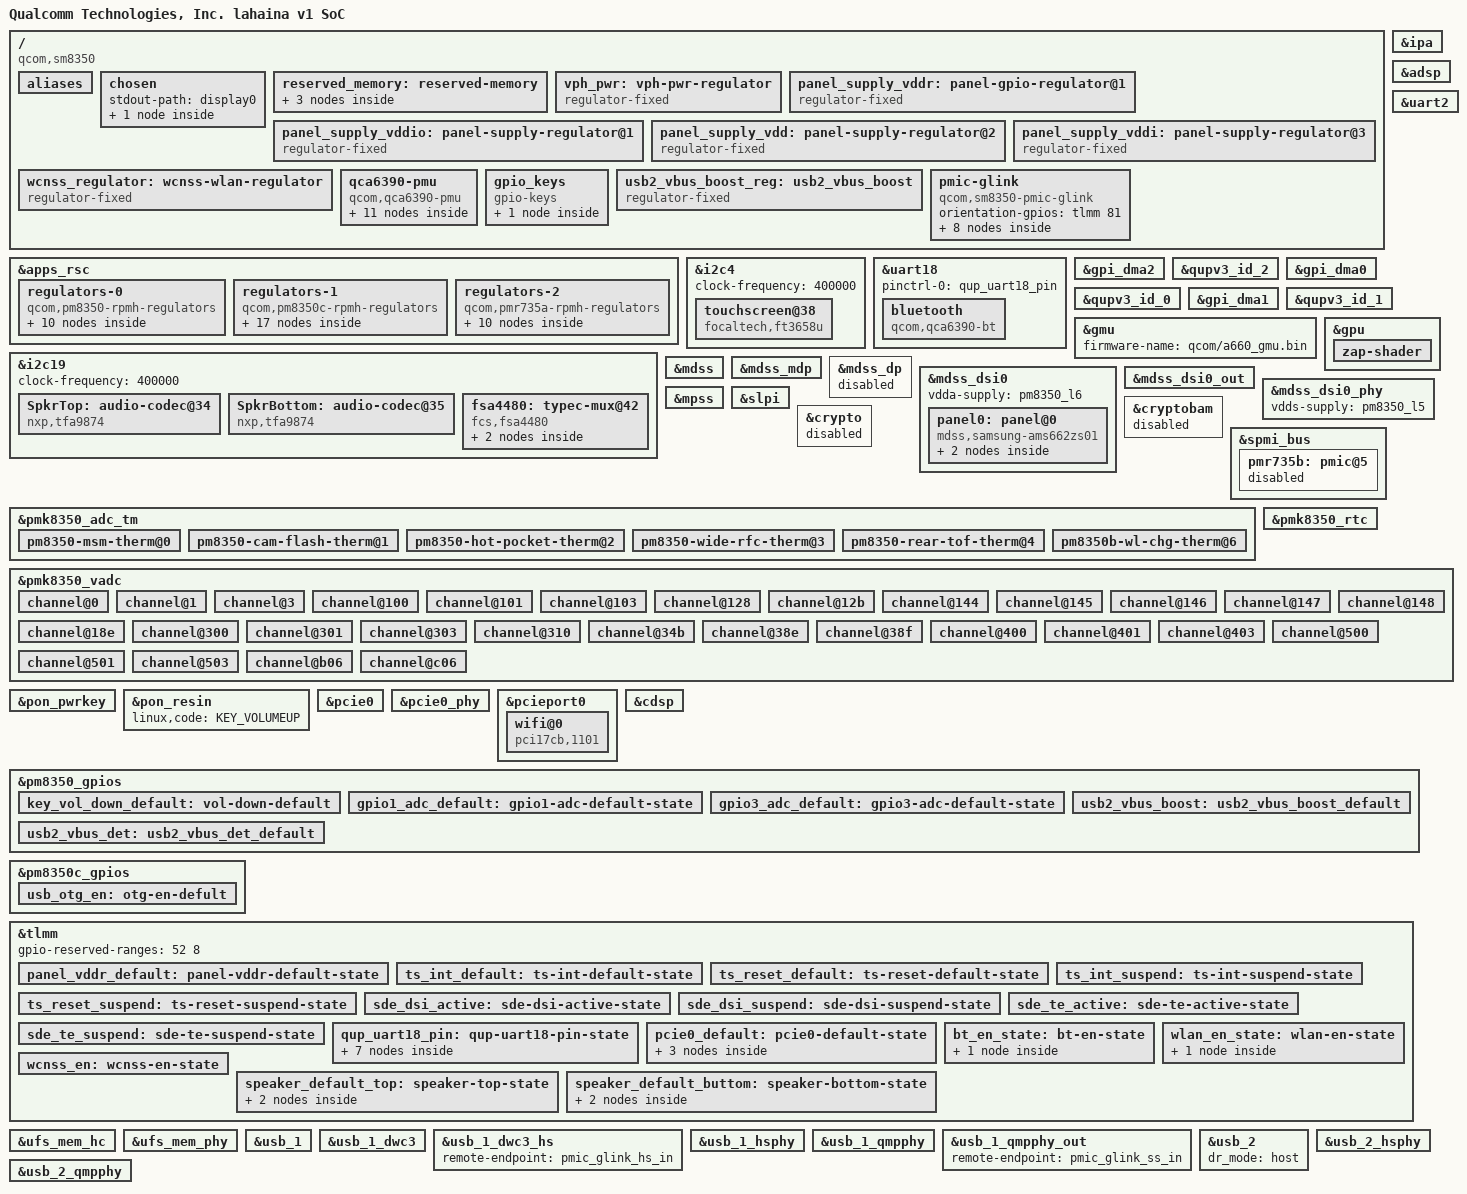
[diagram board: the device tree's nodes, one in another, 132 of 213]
/dts-v1/;

#include <dt-bindings/gpio/gpio.h>
#include <dt-bindings/usb/pd.h>
#include <dt-bindings/arm/qcom,ids.h>
#include <dt-bindings/phy/phy.h>
#include <dt-bindings/interrupt-controller/arm-gic.h>
#include <dt-bindings/regulator/qcom,rpmh-regulator.h>
#include <dt-bindings/dma/qcom-gpi.h>
#include <dt-bindings/pinctrl/qcom,pmic-gpio.h>
#define SMB139x_1_SID 0x0b
#define SMB139x_2_SID 0x0c
#include <dt-bindings/iio/qcom,spmi-adc7-smb139x.h>
#include <dt-bindings/iio/qcom,spmi-adc7-pm8350.h>
#include <dt-bindings/iio/qcom,spmi-adc7-pm8350b.h>
#include <dt-bindings/iio/qcom,spmi-adc7-pmk8350.h>
#include <dt-bindings/iio/qcom,spmi-adc7-pmr735a.h>
#include <dt-bindings/iio/qcom,spmi-adc7-pmr735b.h>
#include "sm8350.dtsi"
#include "pm8350.dtsi"
#include "pm8350b.dtsi"
#include "pm8350c.dtsi"
#include "pmk8350.dtsi"
#include "pmr735a.dtsi"
#include "pmr735b.dtsi"

/ {
	model = "Qualcomm Technologies, Inc. lahaina v1 SoC";
	compatible = "qcom,sm8350", "qcom,lahaina";
	qcom,msm-id = <415 0x10000>, <456 0x10000>;
	qcom,board-id = <0 0>;
        oppo,dtsi_no = <0x5093>;
	interrupt-parent = <&intc>;

	#address-cells = <2>;
	#size-cells = <2>;

        chassis-type = "handset";

	aliases {
                display0 = &panel0;
                serial0 = &uart2;
                hsuart0 = &uart18;
	};

	chosen {
		#address-cells = <2>;
		#size-cells = <2>;
		ranges;
		stdout-path = "display0";

		framebuffer0: framebuffer@e4d00000 {
			compatible = "simple-framebuffer";
			reg = <0x0 0xe4d00000 0x0 0x02300000>;
			width = <1080>;
			height = <2400>;
			stride = <(1080 * 4)>;
			format = "a8r8g8b8";
			clocks = <&gcc GCC_DISP_HF_AXI_CLK>,
				 <&gcc GCC_DISP_SF_AXI_CLK>;
		};
	};

        reserved_memory: reserved-memory {
		#address-cells = <2>;
		#size-cells = <2>;
		ranges;

                splash_memory@e4d00000 {
                        reg = <0x0 0xe4d00000 0x0 0x02300000>;
                        no-map;
                        label = "cont_splash_region";
                };

                ramoops@e9700000 {
                        compatible = "ramoops";
                        reg = <0x0 0xe9700000 0x0 0x05B8000>;
                        record-size = <0x40000>;
                        console-size = <0x40000>;
                        ftrace-size = <0x200000>;
                        pmsg-size = <0x200000>;
                };

                kboot_uboot_logmem@9fe00000 {
                        compatible = "oppo,xbl_uefi_kbootlog";
	                xbluefi-offset = <0x1f7000>;
	                reg = <0x00 0x9fe00000 0x00 0x200000>;
	                phandle = <0x6f5>;
                        no-map;
                };
        };

	vph_pwr: vph-pwr-regulator {
		compatible = "regulator-fixed";
		regulator-name = "vph_pwr";
		regulator-min-microvolt = <3700000>;
		regulator-max-microvolt = <3700000>;
		regulator-always-on;
		regulator-boot-on;
	};

        panel_supply_vddr: panel-gpio-regulator@1 {
                compatible = "regulator-fixed";
                regulator-name = "panel_supply_vddr";
                regulator-min-microvolt = <1800000>;
                regulator-max-microvolt = <1800000>;
                gpio = <&tlmm 163 0x0>;
                enable-active-high;
                regulator-boot-on;
                pinctrl-names = "default";
                pinctrl-0 = <&panel_vddr_default>;

        };

        panel_supply_vddio: panel-supply-regulator@1 {
                compatible = "regulator-fixed";
                regulator-name = "panel_supply_vddio";
                regulator-min-microvolt = <1800000>;
                regulator-max-microvolt = <1800000>;
                regulator-enable-load = <60700>;
                regulator-disable-load = <80>;
                regulator-post-on-sleep = <0>;
        };

        panel_supply_vdd: panel-supply-regulator@2 {
                compatible = "regulator-fixed";
                regulator-name = "panel_supply_vdd";
                regulator-min-microvolt = <3000000>;
                regulator-max-microvolt = <3000000>;
                regulator-enable-load = <10000>;
                regulator-disable-load = <0>;
                regulator-post-on-sleep = <0>;
        };

        panel_supply_vddi: panel-supply-regulator@3 {
                compatible = "regulator-fixed";
                regulator-name = "panel_supply_vddi";
                regulator-min-microvolt = <1800000>;
                regulator-max-microvolt = <1800000>;
        };

        wcnss_regulator: wcnss-wlan-regulator {
                compatible = "regulator-fixed";
                regulator-name = "wcnss_regulator";
                regulator-min-microvolt = <1900000>;
                regulator-max-microvolt = <1900000>;
                enable-active-high;
                wcnss-gpio = <&tlmm 201 GPIO_ACTIVE_HIGH>;
                pinctrl-names = "default";
                pinctrl-0 = <&wcnss_en>;
        };

        qca6390-pmu {
                compatible = "qcom,qca6390-pmu";

                pinctrl-names = "default";
                pinctrl-0 = <&bt_en_state>, <&wlan_en_state>;

                vddaon-supply = <&pmr735a_s2>;
                vddpmu-supply = <&pmr735a_s2>;
                vddrfa0p95-supply = <&pmr735a_s2>;
                vddrfa1p3-supply = <&pm8350_s12>;
                vddrfa1p9-supply = <&pm8350c_s1>;
                vddpcie1p3-supply = <&wcnss_regulator>;
                vddpcie1p9-supply = <&pm8350c_s1>;
                vddio-supply = <&pm8350_s10>;

                bt-enable-gpios = <&tlmm 65 GPIO_ACTIVE_HIGH>;
                wlan-enable-gpios = <&tlmm 64 GPIO_ACTIVE_HIGH>;

                regulators {
                        vreg_pmu_rfa_cmn: ldo0 {
                                regulator-name = "vreg_pmu_rfa_cmn";
                        };

                        vreg_pmu_aon_0p59: ldo1 {
                                regulator-name = "vreg_pmu_aon_0p59";
                        };

                        vreg_pmu_wlcx_0p8: ldo2 {
                                regulator-name = "vreg_pmu_wlcx_0p8";
                        };

                        vreg_pmu_wlmx_0p85: ldo3 {
                                regulator-name = "vreg_pmu_wlmx_0p85";
                        };

                        vreg_pmu_btcmx_0p85: ldo4 {
                                regulator-name = "vreg_pmu_btcmx_0p85";
                        };

                        vreg_pmu_rfa_0p8: ldo5 {
                                regulator-name = "vreg_pmu_rfa_0p8";
                        };

                        vreg_pmu_rfa_1p2: ldo6 {
                                regulator-name = "vreg_pmu_rfa_1p2";
                        };

                        vreg_pmu_rfa_1p7: ldo7 {
                                regulator-name = "vreg_pmu_rfa_1p7";
                        };

                        vreg_pmu_pcie_0p9: ldo8 {
                                regulator-name = "vreg_pmu_pcie_0p9";
                        };

                        vreg_pmu_pcie_1p8: ldo9 {
                                regulator-name = "vreg_pmu_pcie_1p8";
                        };
                };
        };

        gpio_keys {
		compatible = "gpio-keys";
		label = "gpio-keys";
		pinctrl-names = "default";
		pinctrl-0 = <&key_vol_down_default>;
		vol_down {
			label = "volume_down";
			gpios = <&pm8350_gpios 6 GPIO_ACTIVE_LOW>;
			linux,input-type = <1>;
			linux,code = <KEY_VOLUMEDOWN>;
			gpio-key,wakeup;
			debounce-interval = <15>;
			linux,can-disable;
		};
	};

        usb2_vbus_boost_reg: usb2_vbus_boost {
                compatible = "regulator-fixed";
                regulator-name = "usb2_vbus_boost";
                regulator-min-microvolt = <5000000>;
                regulator-max-microvolt = <5000000>;
                gpio = <&pm8350_gpios 8 GPIO_ACTIVE_HIGH>;
                enable-active-high;
        };

	pmic-glink {
		compatible = "qcom,sm8350-pmic-glink", "qcom,pmic-glink";
		#address-cells = <1>;
		#size-cells = <0>;

                /*pinctrl-names = "default", "gpio";
                pinctrl-0 = <&usb_phy_ps &usb_phy_ps1>;*/

                orientation-gpios = <&tlmm 81 GPIO_ACTIVE_HIGH>;

		connector@0 {
			compatible = "usb-c-connector";
			reg = <0>;
			power-role = "dual";
			data-role = "dual";
                        usb-role-switch;   // ADD THIS
			ports {
				#address-cells = <1>;
				#size-cells = <0>;
				port@0 {
					reg = <0>;
					pmic_glink_hs_in: endpoint {
						remote-endpoint = <&usb_1_dwc3_hs>;
					};
				};

                                port@1 {
                                        reg = <1>;
                                        pmic_glink_ss_in: endpoint {
                                                remote-endpoint = <&usb_1_qmpphy_out>;
                                        };
                                };

				port@2 {
					reg = <2>;
					pmic_glink_sbu: endpoint {
						remote-endpoint = <&fsa4480_sbu_mux>;
					};
				};
			};
		};
	};
};

&ipa {
	status = "okay";
	qcom,gsi-loader = "self";
	memory-region = <&pil_ipa_fw_mem>;
	firmware-name = "qcom/sm8350/realme/porsche/ipa_fws.mbn";
};

&adsp {
	status = "okay";
        memory-region = <&pil_adsp_mem>;
	firmware-name = "qcom/sm8350/realme/porsche/adsp.mbn";
};

&apps_rsc {
	regulators-0 {
		compatible = "qcom,pm8350-rpmh-regulators";
		qcom,pmic-id = "b";

		vdd-s1-supply = <&vph_pwr>;
		vdd-s2-supply = <&vph_pwr>;
		vdd-s3-supply = <&vph_pwr>;
		vdd-s4-supply = <&vph_pwr>;
		vdd-s5-supply = <&vph_pwr>;
		vdd-s6-supply = <&vph_pwr>;
		vdd-s7-supply = <&vph_pwr>;
		vdd-s8-supply = <&vph_pwr>;
		vdd-s9-supply = <&vph_pwr>;
		vdd-s10-supply = <&vph_pwr>;
		vdd-s11-supply = <&vph_pwr>;
		vdd-s12-supply = <&vph_pwr>;

		vdd-l1-l4-supply = <&pm8350_s11>;
		vdd-l2-l7-supply = <&vreg_bob>;
		vdd-l3-l5-supply = <&vreg_bob>;
		vdd-l6-l9-l10-supply = <&pm8350_s11>;

		pm8350_s10: smps10 {
			regulator-name = "pm8350_s10";
			regulator-min-microvolt = <1800000>;
			regulator-max-microvolt = <1800000>;
		};

		pm8350_s11: smps11 {
			regulator-name = "pm8350_s11";
			regulator-min-microvolt = <752000>;
			regulator-max-microvolt = <1012000>;
		};

		pm8350_s12: smps12 {
			regulator-name = "pm8350_s12";
			regulator-min-microvolt = <1224000>;
			regulator-max-microvolt = <1360000>;
		};

		pm8350_l1: ldo1 {
			regulator-name = "pm8350_l1";
			regulator-min-microvolt = <912000>;
			regulator-max-microvolt = <920000>;
			regulator-initial-mode = <RPMH_REGULATOR_MODE_HPM>;
			regulator-allow-set-load;
			regulator-allowed-modes = <RPMH_REGULATOR_MODE_LPM
						   RPMH_REGULATOR_MODE_HPM>;
		};

		pm8350_l2: ldo2 {
			regulator-name = "pm8350_l2";
			regulator-min-microvolt = <3072000>;
			regulator-max-microvolt = <3072000>;
			regulator-initial-mode = <RPMH_REGULATOR_MODE_HPM>;
			regulator-allow-set-load;
			regulator-allowed-modes = <RPMH_REGULATOR_MODE_LPM
						   RPMH_REGULATOR_MODE_HPM>;
		};

		pm8350_l3: ldo3 {
			regulator-name = "pm8350_l3";
			regulator-min-microvolt = <904000>;
			regulator-max-microvolt = <904000>;
			regulator-initial-mode = <RPMH_REGULATOR_MODE_HPM>;
			regulator-allow-set-load;
			regulator-allowed-modes = <RPMH_REGULATOR_MODE_LPM
						   RPMH_REGULATOR_MODE_HPM>;
		};

		pm8350_l5: ldo5 {
			regulator-name = "pm8350_l5";
			regulator-min-microvolt = <880000>;
			regulator-max-microvolt = <888000>;
			regulator-initial-mode = <RPMH_REGULATOR_MODE_HPM>;
			regulator-allow-set-load;
			regulator-allowed-modes = <RPMH_REGULATOR_MODE_LPM
						   RPMH_REGULATOR_MODE_HPM>;
		};

		pm8350_l6: ldo6 {
			regulator-name = "pm8350_l6";
			regulator-min-microvolt = <1200000>;
			regulator-max-microvolt = <1208000>;
			regulator-initial-mode = <RPMH_REGULATOR_MODE_HPM>;
			regulator-allow-set-load;
			regulator-allowed-modes = <RPMH_REGULATOR_MODE_LPM
						   RPMH_REGULATOR_MODE_HPM>;
		};

		pm8350_l7: ldo7 {
			regulator-name = "pm8350_l7";
			regulator-min-microvolt = <2400000>;
			regulator-max-microvolt = <3008000>;
			regulator-initial-mode = <RPMH_REGULATOR_MODE_HPM>;
			regulator-allow-set-load;
			regulator-allowed-modes = <RPMH_REGULATOR_MODE_LPM
						   RPMH_REGULATOR_MODE_HPM>;
		};

		pm8350_l9: ldo9 {
			regulator-name = "pm8350_l9";
			regulator-min-microvolt = <1200000>;
			regulator-max-microvolt = <1200000>;
			regulator-initial-mode = <RPMH_REGULATOR_MODE_HPM>;
			regulator-allow-set-load;
			regulator-allowed-modes = <RPMH_REGULATOR_MODE_LPM
						   RPMH_REGULATOR_MODE_HPM>;
		};
	};

	regulators-1 {
		compatible = "qcom,pm8350c-rpmh-regulators";
		qcom,pmic-id = "c";
                qcom,always-wait-for-ack = "true";

		vdd-s1-supply = <&vph_pwr>;
		vdd-s2-supply = <&vph_pwr>;
		vdd-s3-supply = <&vph_pwr>;
		vdd-s4-supply = <&vph_pwr>;
		vdd-s5-supply = <&vph_pwr>;
		vdd-s6-supply = <&vph_pwr>;
		vdd-s7-supply = <&vph_pwr>;
		vdd-s8-supply = <&vph_pwr>;
		vdd-s9-supply = <&vph_pwr>;
		vdd-s10-supply = <&vph_pwr>;

		vdd-l1-l12-supply = <&pm8350c_s1>;
		vdd-l2-l8-supply = <&pm8350c_s1>;
		vdd-l3-l4-l5-l7-l13-supply = <&vreg_bob>;
		vdd-l6-l9-l11-supply = <&vreg_bob>;
		vdd-l10-supply = <&pm8350_s12>;

		vdd-bob-supply = <&vph_pwr>;

		pm8350c_s1: smps1 {
			regulator-name = "pm8350c_s1";
			regulator-min-microvolt = <1800000>;
			regulator-max-microvolt = <1952000>;
		};

		pm8350c_s3: smps3 {
			regulator-name = "pm8350c_s3";
			regulator-min-microvolt = <300000>;
			regulator-max-microvolt = <704000>;
		};

		pm8350c_s10: smps10 {
			regulator-name = "pm8350c_s10";
			regulator-min-microvolt = <1048000>;
			regulator-max-microvolt = <1128000>;
		};

                vreg_bob: bob {
		        regulator-name = "vreg_bob";
		        regulator-min-microvolt = <3008000>;
		        regulator-max-microvolt = <3960000>;
		        regulator-initial-mode = <RPMH_REGULATOR_MODE_AUTO>;
	        };

		pm8350c_l1: ldo1 {
			regulator-name = "pm8350c_l1";
			regulator-min-microvolt = <1800000>;
			regulator-max-microvolt = <1800000>;
			regulator-initial-mode = <RPMH_REGULATOR_MODE_HPM>;
			regulator-allow-set-load;
			regulator-allowed-modes = <RPMH_REGULATOR_MODE_LPM
						   RPMH_REGULATOR_MODE_HPM>;
		};

		pm8350c_l2: ldo2 {
			regulator-name = "pm8350c_l2";
			regulator-min-microvolt = <1800000>;
			regulator-max-microvolt = <1800000>;
			regulator-initial-mode = <RPMH_REGULATOR_MODE_HPM>;
			regulator-allow-set-load;
			regulator-allowed-modes = <RPMH_REGULATOR_MODE_LPM
						   RPMH_REGULATOR_MODE_HPM>;
		};

		pm8350c_l3: ldo3 {
			regulator-name = "pm8350c_l3";
			regulator-min-microvolt = <3000000>;
			regulator-max-microvolt = <3300000>;
			regulator-initial-mode = <RPMH_REGULATOR_MODE_HPM>;
			regulator-allow-set-load;
			regulator-allowed-modes = <RPMH_REGULATOR_MODE_LPM
						   RPMH_REGULATOR_MODE_HPM>;
		};

		pm8350c_l4: ldo4 {
			regulator-name = "pm8350c_l4";
			regulator-min-microvolt = <1704000>;
			regulator-max-microvolt = <3000000>;
			regulator-initial-mode = <RPMH_REGULATOR_MODE_HPM>;
			regulator-allow-set-load;
			regulator-allowed-modes = <RPMH_REGULATOR_MODE_LPM
						   RPMH_REGULATOR_MODE_HPM>;
		};

		pm8350c_l5: ldo5 {
			regulator-name = "pm8350c_l5";
			regulator-min-microvolt = <1704000>;
			regulator-max-microvolt = <3000000>;
			regulator-initial-mode = <RPMH_REGULATOR_MODE_HPM>;
			regulator-allow-set-load;
			regulator-allowed-modes = <RPMH_REGULATOR_MODE_LPM
						   RPMH_REGULATOR_MODE_HPM>;
		};

		pm8350c_l6: ldo6 {
			regulator-name = "pm8350c_l6";
			regulator-min-microvolt = <1800000>;
			regulator-max-microvolt = <2960000>;
			regulator-initial-mode = <RPMH_REGULATOR_MODE_HPM>;
			regulator-allow-set-load;
			regulator-allowed-modes = <RPMH_REGULATOR_MODE_LPM
						   RPMH_REGULATOR_MODE_HPM>;
		};

		pm8350c_l7: ldo7 {
			regulator-name = "pm8350c_l7";
			regulator-min-microvolt = <3008000>;
			regulator-max-microvolt = <3008000>;
			regulator-initial-mode = <RPMH_REGULATOR_MODE_HPM>;
			regulator-allow-set-load;
			regulator-allowed-modes = <RPMH_REGULATOR_MODE_LPM
						   RPMH_REGULATOR_MODE_HPM>;
		};

		pm8350c_l8: ldo8 {
			regulator-name = "pm8350c_l8";
			regulator-min-microvolt = <1800000>;
			regulator-max-microvolt = <1800000>;
			regulator-initial-mode = <RPMH_REGULATOR_MODE_HPM>;
			regulator-allow-set-load;
			regulator-allowed-modes = <RPMH_REGULATOR_MODE_LPM
						   RPMH_REGULATOR_MODE_HPM>;
		};

		pm8350c_l9: ldo9 {
			regulator-name = "pm8350c_l9";
			regulator-min-microvolt = <2960000>;
			/* Originally max = 3008000 but SDHCI expects 2960000 */
			regulator-max-microvolt = <2960000>;
			regulator-initial-mode = <RPMH_REGULATOR_MODE_HPM>;
			regulator-allow-set-load;
			regulator-allowed-modes = <RPMH_REGULATOR_MODE_LPM
						   RPMH_REGULATOR_MODE_HPM>;
		};

		pm8350c_l10: ldo10 {
			regulator-name = "pm8350c_l10";
			regulator-min-microvolt = <1200000>;
			regulator-max-microvolt = <1200000>;
			regulator-initial-mode = <RPMH_REGULATOR_MODE_HPM>;
			regulator-allow-set-load;
			regulator-allowed-modes = <RPMH_REGULATOR_MODE_LPM
						   RPMH_REGULATOR_MODE_HPM>;
		};

		pm8350c_l11: ldo11 {
			regulator-name = "pm8350c_l11";
			regulator-min-microvolt = <2400000>;
			regulator-max-microvolt = <3008000>;
			regulator-initial-mode = <RPMH_REGULATOR_MODE_HPM>;
			regulator-allow-set-load;
			regulator-allowed-modes = <RPMH_REGULATOR_MODE_LPM
						   RPMH_REGULATOR_MODE_HPM>;
		};

		pm8350c_l12: ldo12 {
			regulator-name = "pm8350c_l12";
			regulator-min-microvolt = <1800000>;
			regulator-max-microvolt = <2000000>;
			regulator-initial-mode = <RPMH_REGULATOR_MODE_HPM>;
			regulator-allow-set-load;
			regulator-allowed-modes = <RPMH_REGULATOR_MODE_LPM
						   RPMH_REGULATOR_MODE_HPM>;
		};

		pm8350c_l13: ldo13 {
			regulator-name = "pm8350c_l13";
			regulator-min-microvolt = <3000000>;
			regulator-max-microvolt = <3000000>;
			regulator-initial-mode = <RPMH_REGULATOR_MODE_HPM>;
			regulator-allow-set-load;
			regulator-allowed-modes = <RPMH_REGULATOR_MODE_LPM
						   RPMH_REGULATOR_MODE_HPM>;
		};

	};

	regulators-2 {
		compatible = "qcom,pmr735a-rpmh-regulators";
		qcom,pmic-id = "e";

		vdd-s1-supply = <&vph_pwr>;
		vdd-s2-supply = <&vph_pwr>;
		vdd-s3-supply = <&vph_pwr>;

		vdd-l1-l2-supply = <&pmr735a_s2>;
		vdd-l3-supply = <&pmr735a_s1>;
		vdd-l4-supply = <&pm8350c_s1>;
		vdd-l5-l6-supply = <&pm8350c_s1>;
		vdd-l7-bob-supply = <&vreg_bob>;

		pmr735a_s1: smps1 {
			regulator-name = "pmr735a_s1";
			regulator-min-microvolt = <1200000>;
			regulator-max-microvolt = <1280000>;
		};

		pmr735a_s2: smps2 {
			regulator-name = "pmr735a_s2";
			regulator-min-microvolt = <500000>;
			regulator-max-microvolt = <976000>;
		};

		pmr735a_s3: smps3 {
			regulator-name = "pmr735a_s3";
			regulator-min-microvolt = <2200000>;
			regulator-max-microvolt = <2352000>;
		};

		pmr735a_l1: ldo1 {
			regulator-name = "pmr735a_l1";
			regulator-min-microvolt = <912000>;
			regulator-max-microvolt = <912000>;
			regulator-initial-mode = <RPMH_REGULATOR_MODE_HPM>;
			regulator-allow-set-load;
			regulator-allowed-modes = <RPMH_REGULATOR_MODE_LPM
						   RPMH_REGULATOR_MODE_HPM>;
		};

		pmr735a_l2: ldo2 {
			regulator-name = "pmr735a_l2";
			regulator-min-microvolt = <1200000>;
			regulator-max-microvolt = <1200000>;
			regulator-initial-mode = <RPMH_REGULATOR_MODE_HPM>;
			regulator-allow-set-load;
			regulator-allowed-modes = <RPMH_REGULATOR_MODE_LPM
						   RPMH_REGULATOR_MODE_HPM>;
		};

		pmr735a_l3: ldo3 {
			regulator-name = "pmr735a_l3";
			regulator-min-microvolt = <1200000>;
			regulator-max-microvolt = <1200000>;
			regulator-initial-mode = <RPMH_REGULATOR_MODE_HPM>;
			regulator-allow-set-load;
			regulator-allowed-modes = <RPMH_REGULATOR_MODE_LPM
						   RPMH_REGULATOR_MODE_HPM>;
		};

		pmr735a_l4: ldo4 {
			regulator-name = "pmr735a_l4";
			regulator-min-microvolt = <1776000>;
			regulator-max-microvolt = <1872000>;
			regulator-initial-mode = <RPMH_REGULATOR_MODE_HPM>;
			regulator-allow-set-load;
			regulator-allowed-modes = <RPMH_REGULATOR_MODE_LPM
						   RPMH_REGULATOR_MODE_HPM>;
		};

		pmr735a_l5: ldo5 {
			regulator-name = "pmr735a_l5";
			regulator-min-microvolt = <800000>;
			regulator-max-microvolt = <800000>;
			regulator-initial-mode = <RPMH_REGULATOR_MODE_HPM>;
			regulator-allow-set-load;
			regulator-allowed-modes = <RPMH_REGULATOR_MODE_LPM
						   RPMH_REGULATOR_MODE_HPM>;
		};

		pmr735a_l6: ldo6 {
			regulator-name = "pmr735a_l6";
			regulator-min-microvolt = <480000>;
			regulator-max-microvolt = <904000>;
			regulator-initial-mode = <RPMH_REGULATOR_MODE_HPM>;
			regulator-allow-set-load;
			regulator-allowed-modes = <RPMH_REGULATOR_MODE_LPM
						   RPMH_REGULATOR_MODE_HPM>;
		};

		pmr735a_l7: ldo7 {
			regulator-name = "pmr735a_l7";
			regulator-min-microvolt = <2800000>;
			regulator-max-microvolt = <2800000>;
			regulator-initial-mode = <RPMH_REGULATOR_MODE_HPM>;
			regulator-allow-set-load;
			regulator-allowed-modes = <RPMH_REGULATOR_MODE_LPM
						   RPMH_REGULATOR_MODE_HPM>;
		};
	};
};

&i2c4 {
	clock-frequency = <400000>;
	status = "okay";
        #address-cells = <1>;
        #size-cells = <0>;

        touchscreen@38 {
                compatible = "focaltech,ft3658u";
                reg = <0x38>;
                wakeup-source;
                interrupt-parent = <&tlmm>;
                interrupts = <23 0x2002>;
                reset-gpio = <&tlmm 22 0x00>;
                irq-gpio = <&tlmm 23 0x2002>;
                vdd-supply = <&pm8350c_l11>;
                vcc-i2c-supply = <&pm8350c_l12>;
                pinctrl-names = "default", "suspend";
                pinctrl-0 = <&ts_int_default &ts_reset_default>;
                pinctrl-1 = <&ts_int_suspend &ts_reset_suspend>;
                touchscreen-size-x = <1080>;
                touchscreen-size-y = <2400>;
                focaltech,max-touch-number = <5>;
        };
};

&i2c19 {
       status ="okay";
       clock-frequency = <400000>;
       SpkrTop: audio-codec@34 {
               compatible = "nxp,tfa9874";
               reg = <0x34>;
               reset-gpio = <&tlmm 15 GPIO_ACTIVE_HIGH>;
               first-boost-trip-lvl = <0x9>;
               max-coil-current = <0xf>;
               pinctrl-names = "default";
               pinctrl-0 = <&speaker_default_top>;
               sound-name-prefix = "Top";
               #sound-dai-cells = <1>;
               status = "okay";
       };

       SpkrBottom: audio-codec@35 {
               compatible = "nxp,tfa9874";
               reg = <0x35>;
               reset-gpio = <&tlmm 42 GPIO_ACTIVE_HIGH>;
               first-boost-trip-lvl = <0x9>;
               max-coil-current = <0xf>;
               pinctrl-names = "default";
               pinctrl-0 = <&speaker_default_buttom>;
               sound-name-prefix = "Bottom";
               #sound-dai-cells = <1>;
               status = "okay";
       };

       fsa4480: typec-mux@42 {
	       compatible = "fcs,fsa4480";
	       reg = <0x42>;
	       interrupts-extended = <&tlmm 2 IRQ_TYPE_LEVEL_LOW>;
	       vcc-supply = <&vreg_bob>;
	       mode-switch;
	       orientation-switch;
	       port {
			fsa4480_sbu_mux: endpoint {
				remote-endpoint = <&pmic_glink_sbu>;
			};
		};
        };
};

&uart2 {
        status = "okay";
};

&uart18 {
        status = "okay";
        pinctrl-names = "default";
        pinctrl-0 = <&qup_uart18_pin>;

        bluetooth {
                compatible = "qcom,qca6390-bt";
		vddrfacmn-supply = <&vreg_pmu_rfa_cmn>;
		vddaon-supply = <&vreg_pmu_aon_0p59>;
		vddbtcmx-supply = <&vreg_pmu_btcmx_0p85>;
		vddrfa0p8-supply = <&vreg_pmu_rfa_0p8>;
		vddrfa1p2-supply = <&vreg_pmu_rfa_1p2>;
		vddrfa1p7-supply = <&vreg_pmu_rfa_1p7>;
        };
};

&gpi_dma2 {
	status = "okay";
};

&qupv3_id_2 {
	status = "okay";
};

&gpi_dma0 {
	status = "okay";
};

&qupv3_id_0 {
	status = "okay";
};

&gpi_dma1 {
	status = "okay";
};

&qupv3_id_1 {
	status = "okay";
};

&gmu {
        status = "okay";
        firmware-name = "qcom/a660_gmu.bin";
};

&gpu {
        status = "okay";
        zap-shader {
                memory-region = <&pil_gpu_mem>;
                firmware-name = "qcom/a660_zap.mbn";
        };
};

&mdss {
        status = "okay";
};

&mdss_mdp {
        status = "okay";
};

&mdss_dp {
        status = "disabled";
};

&mdss_dsi0 {
        status = "okay";
        vdda-supply = <&pm8350_l6>;
        panel0: panel@0 {
                compatible = "mdss,samsung-ams662zs01";
                reg = <0>;
                vddio-supply = <&panel_supply_vddio>;
                vddr-supply = <&panel_supply_vddr>;
                vddi-supply = <&panel_supply_vddi>;
                vdd-supply = <&panel_supply_vdd>;
                reset-gpios = <&tlmm 24 GPIO_ACTIVE_LOW>;
                pinctrl-names = "default", "sleep";
                pinctrl-0 = <&sde_dsi_active &sde_te_active>;
                pinctrl-1 = <&sde_dsi_suspend &sde_te_suspend>;
                status = "okay";
                port {
                        panel_in: endpoint {
                                remote-endpoint = <&mdss_dsi0_out>;
                        };
                };
        };
};

&mdss_dsi0_out {
        data-lanes = <0 1 2 3>;
        remote-endpoint = <&panel_in>;
};

&mdss_dsi0_phy {
        status = "okay";
        vdds-supply = <&pm8350_l5>;
};

&mpss {
        memory-region = <&pil_modem_mem>;
	firmware-name = "qcom/sm8350/realme/porsche/modem.mbn";
	status = "okay";
};

&slpi {
        memory-region = <&pil_slpi_mem>;
	firmware-name = "qcom/sm8350/realme/porsche/slpi.mbn";
	status = "okay";
};

&cryptobam {
	status = "disabled";
};

&crypto {
	status = "disabled";
};

&spmi_bus {
        pmr735b: pmic@5 {
                status = "disabled";
        };
};

&pmk8350_adc_tm {
	status = "okay";

	pm8350-msm-therm@0 {
		reg = <0>;
		io-channels = <&pmk8350_vadc PM8350_ADC7_AMUX_THM1_100K_PU(1)>;
		qcom,ratiometric;
		qcom,hw-settle-time-us = <200>;
	};

	pm8350-cam-flash-therm@1 {
		reg = <1>;
		io-channels = <&pmk8350_vadc PM8350_ADC7_AMUX_THM2_100K_PU(1)>;
		qcom,ratiometric;
		qcom,hw-settle-time-us = <200>;
	};

	pm8350-hot-pocket-therm@2 {
		reg = <2>;
		io-channels = <&pmk8350_vadc PM8350_ADC7_AMUX_THM3_100K_PU(1)>;
		qcom,ratiometric;
		qcom,hw-settle-time-us = <200>;
	};

	pm8350-wide-rfc-therm@3 {
		reg = <3>;
		io-channels = <&pmk8350_vadc PM8350_ADC7_AMUX_THM4_100K_PU(1)>;
		qcom,ratiometric;
		qcom,hw-settle-time-us = <200>;
	};

	pm8350-rear-tof-therm@4 {
		reg = <4>;
		io-channels = <&pmk8350_vadc PM8350_ADC7_AMUX_THM5_100K_PU(1)>;
		qcom,ratiometric;
		qcom,hw-settle-time-us = <200>;
	};

	pm8350b-wl-chg-therm@6 {
		reg = <6>;
		io-channels = <&pmk8350_vadc PM8350B_ADC7_GPIO2_100K_PU>;
		qcom,ratiometric;
		qcom,hw-settle-time-us = <200>;
	};
};

&pmk8350_rtc {
	status = "okay";
};

&pmk8350_vadc {
	status = "okay";
	pinctrl-0 = <&gpio1_adc_default>, <&gpio3_adc_default>;
	pinctrl-names = "default";

	channel@0 {
		reg = <0x00>;
		qcom,pre-scaling = <1 1>;
		label = "pmk8350_ref_gnd";
	};

	channel@1 {
		reg = <0x01>;
		qcom,pre-scaling = <1 1>;
		label = "pmk8350_vref_1p25";
	};

	channel@3 {
		reg = <0x03>;
		qcom,pre-scaling = <1 1>;
		label = "pmk8350_die_temp";
	};

	channel@100 {
		reg = <0x100>;
		qcom,pre-scaling = <1 1>;
		label = "pm8350_ref_gnd";
	};

	channel@101 {
		reg = <0x101>;
		qcom,pre-scaling = <1 1>;
		label = "pm8350_vref_1p25";
	};

	channel@103 {
		reg = <0x103>;
		qcom,pre-scaling = <1 1>;
		label = "pm8350_die_temp";
	};

	channel@128 {
		reg = <0x128>;
		qcom,ratiometric;
		qcom,hw-settle-time = <700>;
		qcom,pre-scaling = <1 1>;
		label = "gpio1_v";
	};

	channel@12b {
		reg = <0x12b>;
		qcom,ratiometric;
		qcom,hw-settle-time = <700>;
		qcom,pre-scaling = <1 1>;
		label = "gpio3_v";
	};

	channel@144 {
		reg = <PM8350_ADC7_AMUX_THM1_100K_PU(1)>;
		qcom,ratiometric;
		qcom,hw-settle-time = <200>;
		qcom,pre-scaling = <1 1>;
		label = "pm8350_msm_therm";
	};

	channel@145 {
		reg = <PM8350_ADC7_AMUX_THM2_100K_PU(1)>;
		qcom,ratiometric;
		qcom,hw-settle-time = <200>;
		qcom,pre-scaling = <1 1>;
		label = "pm8350_cam_flash_therm";
	};

	channel@146 {
		reg = <PM8350_ADC7_AMUX_THM3_100K_PU(1)>;
		qcom,ratiometric;
		qcom,hw-settle-time = <200>;
		qcom,pre-scaling = <1 1>;
		label = "pm8350_hot_pocket_therm";
	};

	channel@147 {
		reg = <PM8350_ADC7_AMUX_THM4_100K_PU(1)>;
		qcom,ratiometric;
		qcom,hw-settle-time = <200>;
		qcom,pre-scaling = <1 1>;
		label = "pm8350_wide_rfc_therm";
	};

	channel@148 {
		reg = <PM8350_ADC7_AMUX_THM5_100K_PU(1)>;
		qcom,ratiometric;
		qcom,hw-settle-time = <200>;
		qcom,pre-scaling = <1 1>;
		label = "pm8350_rear_tof_therm";
	};

	channel@18e {
		reg = <0x18e>;
		qcom,pre-scaling = <1 3>;
		label = "pm8350_vph_pwr";
	};

	channel@300 {
		reg = <0x300>;
		qcom,pre-scaling = <1 1>;
		label = "pm8350b_ref_gnd";
	};

	channel@301 {
		reg = <0x301>;
		qcom,pre-scaling = <1 1>;
		label = "pm8350b_vref_1p25";
	};

	channel@303 {
		reg = <0x303>;
		qcom,pre-scaling = <1 1>;
		label = "pm8350b_die_temp";
	};

	channel@310 {
		reg = <PM8350B_ADC7_CHG_TEMP>;
		qcom,pre-scaling = <1 1>;
		label = "pm8350b_chg_temp";
	};

	channel@34b {
		reg = <PM8350B_ADC7_GPIO2_100K_PU>;
		qcom,ratiometric;
		qcom,hw-settle-time = <200>;
		qcom,pre-scaling = <1 1>;
		label = "pm8350b_wl_chg_therm";
	};

	channel@38e {
		reg = <0x38e>;
		qcom,pre-scaling = <1 3>;
		label = "pm8350b_vph_pwr";
	};

	channel@38f {
		reg = <0x38f>;
		qcom,pre-scaling = <1 3>;
		label = "pm8350b_vbat_sns";
	};

	channel@400 {
		reg = <0x400>;
		qcom,pre-scaling = <1 1>;
		label = "pmr735a_ref_gnd";
	};

	channel@401 {
		reg = <0x401>;
		qcom,pre-scaling = <1 1>;
		label = "pmr735a_vref_1p25";
	};

	channel@403 {
		reg = <0x403>;
		qcom,pre-scaling = <1 1>;
		label = "pmr735a_die_temp";
	};

	channel@500 {
		reg = <0x500>;
		qcom,pre-scaling = <1 1>;
		label = "pmr735b_ref_gnd";
	};

	channel@501 {
		reg = <0x501>;
		qcom,pre-scaling = <1 1>;
		label = "pmr735b_vref_1p25";
	};

	channel@503 {
		reg = <0x503>;
		qcom,pre-scaling = <1 1>;
		label = "pmr735b_die_temp";
	};

	channel@b06 {
		reg = <SMB139x_1_ADC7_SMB_TEMP>;
		qcom,pre-scaling = <1 1>;
		label = "smb139x_1_smb_temp";
	};

	channel@c06 {
		reg = <SMB139x_2_ADC7_SMB_TEMP>;
		qcom,pre-scaling = <1 1>;
		label = "smb139x_2_smb_temp";
	};
};

&pon_pwrkey {
	status = "okay";
};

&pon_resin {
	linux,code = <KEY_VOLUMEUP>;
	status = "okay";
};

&pcie0 {
        status = "okay";
        pinctrl-names = "default";
        pinctrl-0 = <&pcie0_default>;
        perst-gpios = <&tlmm 94 GPIO_ACTIVE_LOW>;
        wake-gpios = <&tlmm 96 GPIO_ACTIVE_HIGH>;
};

&pcie0_phy {
        vdda-phy-supply = <&pm8350_l5>;
        vdda-pll-supply = <&pm8350_l6>;
        status = "okay";
};

&pcieport0 {
	wifi@0 {
		compatible = "pci17cb,1101";
		reg = <0x10000 0x0 0x0 0x0 0x0>;

		vddrfacmn-supply = <&vreg_pmu_rfa_cmn>;
		vddaon-supply = <&vreg_pmu_aon_0p59>;
		vddwlcx-supply = <&vreg_pmu_wlcx_0p8>;
		vddwlmx-supply = <&vreg_pmu_wlmx_0p85>;
		vddrfa0p8-supply = <&vreg_pmu_rfa_0p8>;
		vddrfa1p2-supply = <&vreg_pmu_rfa_1p2>;
		vddrfa1p7-supply = <&vreg_pmu_rfa_1p7>;
		vddpcie0p9-supply = <&vreg_pmu_pcie_0p9>;
		vddpcie1p8-supply = <&vreg_pmu_pcie_1p8>;

		qcom,ath11k-calibration-variant = "Realme_Gt_2";
	};
};

&cdsp {
	status = "okay";
        memory-region = <&pil_cdsp_mem>;
	firmware-name = "qcom/sm8350/realme/porsche/cdsp.mbn";
};

&pm8350_gpios {
	status = "okay";

	key_vol_down_default: vol-down-default {
		pins = "gpio6";
		function = "normal";
		input-enable;
		bias-pull-up;
		power-source = <1>;
	};

	gpio1_adc_default: gpio1-adc-default-state {
		pins = "gpio1";
		function = "normal";
		bias-high-impedance;
		bias-disable;
	};

	gpio3_adc_default: gpio3-adc-default-state {
		pins = "gpio3";
		function = "normal";
		bias-high-impedance;
		bias-disable;
	};

        usb2_vbus_boost: usb2_vbus_boost_default {
                pins = "gpio8";
                function = "normal";
                output-low;
                power-source = <0x00>;
                phandle = <0x5e8>;
        };

        usb2_vbus_det: usb2_vbus_det_default {
                pins = "gpio9";
                function = "normal";
                input-enable;
                bias-disable;
                power-source = <0x00>;
                phandle = <0x5e7>;
        };
};

&pm8350c_gpios {
	status = "okay";
                usb_otg_en: otg-en-defult {
	        pins = "gpio1";
	        function = "normal";
	        drive-strength = <2>;
	        bias-disable;
	        output-high;
        };
};

&tlmm {
	gpio-reserved-ranges = <52 8>;

        panel_vddr_default: panel-vddr-default-state {
                pins = "gpio163";
                function = "gpio";
                drive-strength = <8>;
                bias-disable = <0>;
                output-high;
        };

	ts_int_default: ts-int-default-state {
		pins = "gpio23";
		function = "gpio";
		drive-strength = <8>;
		bias-pull-down;
                input-enable;
	};

	ts_reset_default: ts-reset-default-state {
		pins = "gpio22";
		function = "gpio";
		drive-strength = <8>;
		output-high;
        };

	ts_int_suspend: ts-int-suspend-state {
		pins = "gpio23";
		function = "gpio";
		drive-strength = <2>;
		bias-pull-down;
                input-enable;
	};

	ts_reset_suspend: ts-reset-suspend-state {
		pins = "gpio22";
		function = "gpio";
		drive-strength = <2>;
		bias-disable;
                output-low;
	};

        sde_dsi_active: sde-dsi-active-state {
		pins = "gpio24";
		function = "gpio";
		drive-strength = <8>;
		bias-disable;
	};

	sde_dsi_suspend: sde-dsi-suspend-state {
		pins = "gpio24";
		function = "gpio";
		drive-strength = <2>;
		bias-pull-down;
	};

	sde_te_active: sde-te-active-state {
		pins = "gpio82";
		function = "mdp_vsync";
		drive-strength = <2>;
		bias-pull-down;
	};

	sde_te_suspend: sde-te-suspend-state {
		pins = "gpio82";
		function = "mdp_vsync";
		drive-strength = <2>;
		bias-pull-down;
	};

        qup_uart18_pin: qup-uart18-pin-state {
                default-cts-pin {
                        pins = "gpio68";
                        function = "gpio";
                        drive-strength = <2>;
                };
                default-rts-rx-pin {
                        pins = "gpio69", "gpio71";
                        function = "gpio";
                        drive-strength = <2>;
                        bias-pull-down;
                };
                default-tx-pin {
                        pins = "gpio70";
                        function = "gpio";
                        drive-strength = <2>;
                        bias-pull-up;
                };
                cts-rx-pin {
                        pins = "gpio68", "gpio71";
                        function = "qup18";
                        drive-strength = <2>;
                        bias-disable;
                };
                rts-pin {
                        pins = "gpio69";
                        function = "qup18";
                        drive-strength = <2>;
                        bias-pull-down;
                };
                tx-pin {
                        pins = "gpio70";
                        function = "qup18";
                        drive-strength = <2>;
                        bias-pull-up;
                };
                usb2-id-pin {
                        pins = "gpio51";
                        function = "gpio";
                        input-enable;
                        bias-pull-up;
               };
        };

	pcie0_default: pcie0-default-state {
		perst-pins {
			pins = "gpio94";
			function = "gpio";
			drive-strength = <2>;
			bias-pull-down;
		};

		clkreq-pins {
			pins = "gpio95";
			function = "pcie0_clkreqn";
			drive-strength = <2>;
			bias-pull-up;
		};

		wake-pins {
			pins = "gpio96";
			function = "gpio";
			drive-strength = <2>;
			bias-pull-up;
		};
        };

        bt_en_state: bt-en-state {
                bt-en {
                        pins = "gpio65";
                        function = "gpio";
                        drive-strength = <16>;
                        output-high;
                        bias-pull-up;
                };
        };

        wlan_en_state: wlan-en-state {
                wlan-en {
                        pins = "gpio64";
                        function = "gpio";
                        drive-strength = <16>;
                        output-high;
                        bias-pull-up;
                };
        };

	wcnss_en: wcnss-en-state {
		pins = "gpio201";
		function = "gpio";
		drive-strength = <16>;
		bias-pull-down;
		output-low;
	};

	speaker_default_top: speaker-top-state {
		active-pins {
			pins = "gpio15";
			function = "gpio";
			drive-strength = <16>;
			bias-disable;
                        output-high;
		};

		sleep-pins {
			pins = "gpio15";
			function = "gpio";
			drive-strength = <2>;
			bias-pull-down;
                        input-enable;
		};
        };

	speaker_default_buttom: speaker-bottom-state {
		active-pins {
			pins = "gpio42";
			function = "gpio";
			drive-strength = <16>;
			bias-disable;
                        output-high;
		};

		sleep-pins {
			pins = "gpio42";
			function = "gpio";
			drive-strength = <2>;
			bias-pull-down;
                        input-enable;
		};
        };

        /*usb_phy_ps: usb3phy-portselect-default {
                active-pins {
                        function = "usb_phy";
                        pins = "gpio81";
                        bias-disable;
                        drive-strength = <2>;
                };

                sleep-pins {
                        function = "gpio";
                        pins = "gpio81";
                        drive-strength = <2>;
                        bias-disable;
                        input-enable;
                };
        };*/
};

&ufs_mem_hc {
	reset-gpios = <&tlmm 203 GPIO_ACTIVE_LOW>;
	vcc-supply = <&pm8350_l7>;
	vcc-voltage-level = <2504000 2950000>;
	vcc-max-microamp = <800000>;
	vccq-supply = <&pm8350_l9>;
	vccq-max-microamp = <900000>;
	qcom,vddp-ref-clk-supply = <&pm8350_l9>;
	qcom,vddp-ref-clk-max-microamp = <100>;
	qcom,vccq-parent-supply = <&pm8350_s12>;
	qcom,vccq-parent-max-microamp = <210000>;
        status = "okay";
};

&ufs_mem_phy {
	vdda-phy-supply = <&pm8350_l5>;
	vdda-phy-always-on;
	vdda-max-microamp = <91600>;
	vdda-pll-supply = <&pm8350_l6>;
	vdda-pll-max-microamp = <19000>;
        status = "okay";
};

&usb_1 {
	/delete-property/ interconnects;
	/delete-property/ interconnect-names;
        qcom,select-utmi-as-pipe-clk;
        vbus-supply = <&usb2_vbus_boost_reg>;
        status = "okay";
};

&usb_1_dwc3 {
       dr_mode = "otg";
       maximum-speed = "high-speed";
       phys = <&usb_1_hsphy>;
       phy-names = "usb2-phy";
       usb-role-switch;
       vbus-det-gpio = <&pm8350_gpios 9 GPIO_ACTIVE_HIGH>;
       //pinctrl-names = "default";
       //pinctrl-0 = <&usb_otg_en>;
};

&usb_1_dwc3_hs {
	remote-endpoint = <&pmic_glink_hs_in>;
};

&usb_1_hsphy {
	vdda-pll-supply = <&pm8350_l5>;
	vdda18-supply = <&pm8350c_l1>;
	vdda33-supply = <&pm8350_l2>;
        status = "okay";
};

&usb_1_qmpphy {
	vdda-phy-supply = <&pm8350_l6>;
	vdda-pll-supply = <&pm8350_l1>;
        status = "okay";
};

&usb_1_qmpphy_out {
	remote-endpoint = <&pmic_glink_ss_in>;
};

&usb_2 {
        dr_mode = "host";
	status = "okay";
};

&usb_2_hsphy {
	vdda-pll-supply = <&pm8350_l5>;
	vdda18-supply = <&pm8350c_l1>;
	vdda33-supply = <&pm8350_l2>;
        status = "okay";
};

&usb_2_qmpphy {
	vdda-phy-supply = <&pm8350_l6>;
	vdda-pll-supply = <&pm8350_l5>;
        status = "okay";
};
